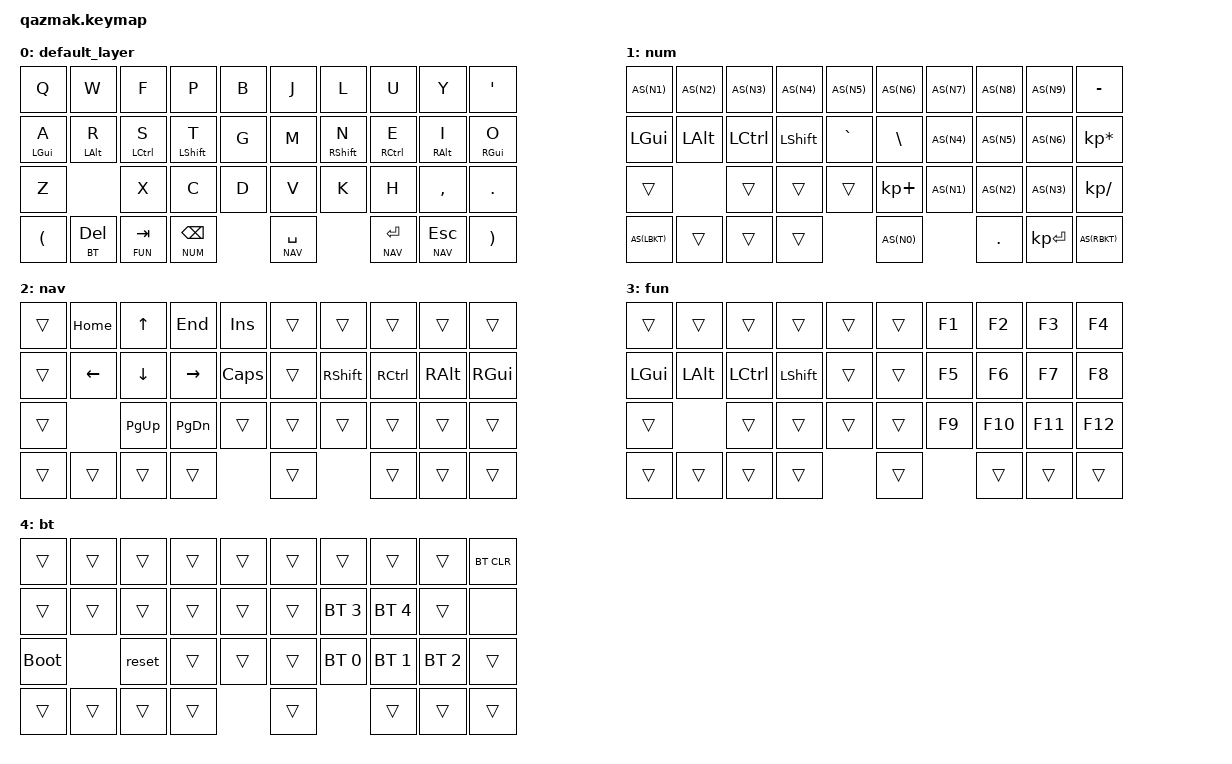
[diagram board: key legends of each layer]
/*
 * Copyright (c) 2020 The ZMK Contributors
 *
 * SPDX-License-Identifier: MIT
 */

#include <behaviors.dtsi>
#include <dt-bindings/zmk/keys.h>
#include <dt-bindings/zmk/bt.h>

#define DEFAULT 0
#define NUM     1
#define NAV     2
#define FUN     3
#define BT      4

#define AS(keycode) &as LS(keycode) keycode

&lt { quick_tap_ms = <140>; };

/ {
    behaviors {
        hm: homerow_mods {
            compatible = "zmk,behavior-hold-tap";
            label = "homerow mods";
            #binding-cells = <2>;
            tapping-term-ms = <180>;
            quick-tap-ms = <140>;
            flavor = "tap-preferred";
            bindings = <&kp>, <&kp>;
        };
        
        as: auto_shift {
            compatible = "zmk,behavior-hold-tap";
            label = "AUTO_SHIFT";
            #binding-cells = <2>;
            tapping_term_ms = <180>;
            quick_tap_ms = <0>;
            flavor = "tap-preferred";
            bindings = <&kp>, <&kp>;
        };        
    };
};
/ {
    combos {
        compatible = "zmk,combos";
        combo_esc {
            timeout-ms = <25>;
            key-positions = <0 1>;
            bindings = <&kp ESC>;
        };
        
        combo_tab {
            timeout-ms = <25>;
            key-positions = <10 11>;
            bindings = <&kp TAB>;
        }; 
        
        combo_caps {
            timeout-ms = <25>;
            key-positions = <20 21>;
            bindings = <&caps_word>;
        };
        
        combo_bspc {
            timeout-ms = <25>;
            key-positions = <8 9>;
            bindings = <&kp BSPC>;
        };
        
        combo_semi {
            timeout-ms = <25>;
            key-positions = <18 19>;
            bindings = <&kp SEMI>;
        }; 
        
        combo_slash {
            timeout-ms = <25>;
            key-positions = <27 28>;
            bindings = <&kp FSLH>;
        };  
        
   };
};

/ {
    keymap {
        compatible = "zmk,keymap";
        default_layer {
            bindings = <
    &kp Q      &kp W        &kp F       &kp P       &kp B  &kp J  &kp L       &kp U       &kp Y       &kp SQT
    &hm LGUI A &hm LALT R   &hm LCTRL S &hm LSHFT T &kp G  &kp M  &hm RSHFT N &hm RCTRL E &hm RALT I  &hm RGUI O
    &kp Z                   &kp X       &kp C       &kp D  &kp V  &kp K       &kp H       &kp COMMA   &kp DOT
    &kp LPAR   &lt BT DEL   &lt FUN TAB &lt NUM BSPC       &lt NAV SPACE      &lt NAV RET &lt NAV ESC &kp RPAR
            >;
        };
        num {
            bindings = <
    AS(N1)     AS(N2)     AS(N3)     AS(N4)      AS(N5)    AS(N6)      AS(N7)      AS(N8)      AS(N9)    &kp MINUS
    &kp LGUI   &kp LALT   &kp LCTRL  &kp LSHFT   &kp GRAVE &kp BSLH    AS(N4)      AS(N5)      AS(N6)    &kp KP_MULTIPLY
    &trans                &trans     &trans      &trans    &kp KP_PLUS AS(N1)      AS(N2)      AS(N3)    &kp KP_DIVIDE
    AS(LBKT)   &trans     &trans     &trans              AS(N0)                    &kp DOT     &kp KP_ENTER AS(RBKT)
            >;
        };

        nav {
            bindings = <
    &trans  &kp HOME   &kp UP     &kp END     &kp INS  &trans   &trans    &trans      &trans      &trans
    &trans  &kp LEFT   &kp DOWN   &kp RIGHT   &kp CAPS &trans   &kp RSHFT &kp RCTRL   &kp RALT    &kp RGUI
    &trans             &kp PG_UP  &kp PG_DN   &trans   &trans   &trans    &trans      &trans      &trans      
    &trans  &trans     &trans     &trans               &trans             &trans      &trans      &trans
            >;
        };
        
        fun {
            bindings = <
    &trans     &trans     &trans     &trans      &trans &trans &kp F1      &kp F2      &kp F3    &kp F4 
    &kp LGUI   &kp LALT   &kp LCTRL  &kp LSHFT   &trans &trans &kp F5      &kp F6      &kp F7    &kp F8 
    &trans                &trans     &trans      &trans &trans &kp F9      &kp F10     &kp F11   &kp F12
    &trans     &trans     &trans     &trans             &trans             &trans      &trans    &trans
            >;
        };   
        
        bt {
            bindings = <
    &trans     &trans     &trans     &trans      &trans &trans   &trans       &trans       &trans       &bt BT_CLR
    &trans     &trans     &trans     &trans      &trans &trans   &bt BT_SEL 3 &bt BT_SEL 4 &trans       &none
    &bootloader           &reset     &trans      &trans &trans   &bt BT_SEL 0 &bt BT_SEL 1 &bt BT_SEL 2 &trans      
    &trans     &trans     &trans     &trans             &trans                &trans       &trans       &trans
            >;
        };        
    };
};
